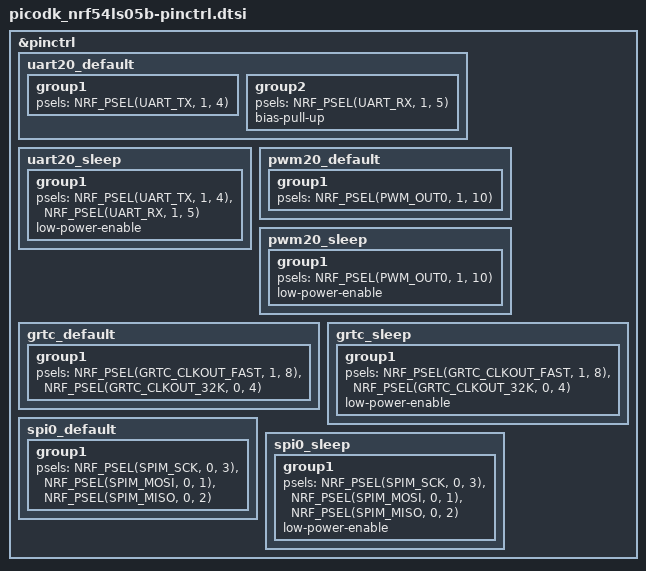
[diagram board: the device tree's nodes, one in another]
/*
 * Copyright (c) 2025 Nordic Semiconductor ASA
 *
 * SPDX-License-Identifier: LicenseRef-Nordic-5-Clause
 */

&pinctrl {
	/omit-if-no-ref/ uart20_default: uart20_default {
		group1 {
			psels = <NRF_PSEL(UART_TX, 1, 4)>;
		};

		group2 {
			psels = <NRF_PSEL(UART_RX, 1, 5)>;
			bias-pull-up;
		};
	};

	/omit-if-no-ref/ uart20_sleep: uart20_sleep {
		group1 {
			psels = <NRF_PSEL(UART_TX, 1, 4)>,
				<NRF_PSEL(UART_RX, 1, 5)>;
			low-power-enable;
		};
	};

	/omit-if-no-ref/ pwm20_default: pwm20_default {
		group1 {
			psels = <NRF_PSEL(PWM_OUT0, 1, 10)>;
		};
	};

	/omit-if-no-ref/ pwm20_sleep: pwm20_sleep {
		group1 {
			psels = <NRF_PSEL(PWM_OUT0, 1, 10)>;
			low-power-enable;
		};
	};

	/omit-if-no-ref/ grtc_default: grtc_default {
		group1 {
			psels = <NRF_PSEL(GRTC_CLKOUT_FAST, 1, 8)>,
				<NRF_PSEL(GRTC_CLKOUT_32K, 0, 4)>;
		};
	};

	/omit-if-no-ref/ grtc_sleep: grtc_sleep {
		group1 {
			psels = <NRF_PSEL(GRTC_CLKOUT_FAST, 1, 8)>,
				<NRF_PSEL(GRTC_CLKOUT_32K, 0, 4)>;
			low-power-enable;
		};
	};


	spi0_default: spi0_default {
		group1 {
			psels = <NRF_PSEL(SPIM_SCK, 0, 3)>,
			        <NRF_PSEL(SPIM_MOSI, 0, 1)>,
			        <NRF_PSEL(SPIM_MISO, 0, 2)>;
		};
	};

	spi0_sleep: spi0_sleep {
		group1 {
			psels = <NRF_PSEL(SPIM_SCK, 0, 3)>,
			        <NRF_PSEL(SPIM_MOSI, 0, 1)>,
			        <NRF_PSEL(SPIM_MISO, 0, 2)>;
			low-power-enable;
		};
	};

};
